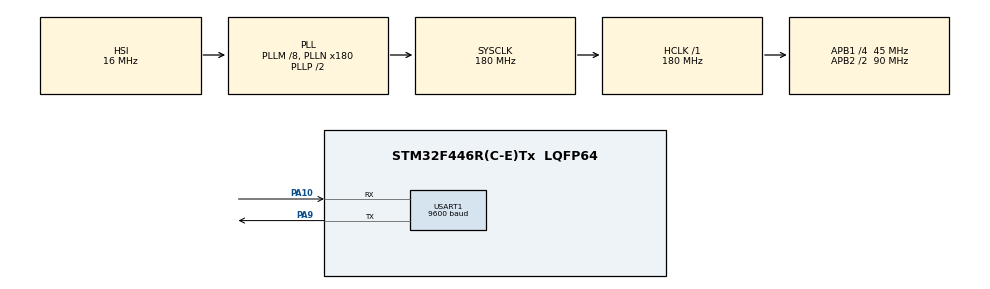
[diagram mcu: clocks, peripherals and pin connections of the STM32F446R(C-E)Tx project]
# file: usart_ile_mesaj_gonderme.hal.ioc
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Dma.Request0=USART1_TX
Dma.USART1_TX.0.Direction=DMA_MEMORY_TO_PERIPH
Dma.USART1_TX.0.FIFOMode=DMA_FIFOMODE_DISABLE
Dma.USART1_TX.0.Instance=DMA2_Stream7
Dma.USART1_TX.0.MemDataAlignment=DMA_MDATAALIGN_BYTE
Dma.USART1_TX.0.MemInc=DMA_MINC_ENABLE
Dma.USART1_TX.0.Mode=DMA_CIRCULAR
Dma.USART1_TX.0.PeriphDataAlignment=DMA_PDATAALIGN_BYTE
Dma.USART1_TX.0.PeriphInc=DMA_PINC_DISABLE
Dma.USART1_TX.0.Priority=DMA_PRIORITY_LOW
Mcu.Family=STM32F4
Mcu.Name=STM32F446R(C-E)Tx
Mcu.Package=LQFP64
NVIC.DMA2_Stream7_IRQn=true\:0\:0\:false\:false\:true\:false\:true\:true
NVIC.PriorityGroup=NVIC_PRIORITYGROUP_4
NVIC.USART1_IRQn=true\:0\:0\:false\:false\:true\:true\:true\:true
PA10.Mode=Asynchronous
PA10.Signal=USART1_RX
PA13.Mode=Serial_Wire
PA13.Signal=SYS_JTMS-SWDIO
PA14.Mode=Serial_Wire
PA14.Signal=SYS_JTCK-SWCLK
PA9.Mode=Asynchronous
PA9.Signal=USART1_TX
ProjectManager.HeapSize=0x200
ProjectManager.StackSize=0x400
ProjectManager.TargetToolchain=STM32CubeIDE
RCC.AHBFreq_Value=180000000
RCC.APB1CLKDivider=RCC_HCLK_DIV4
RCC.APB1Freq_Value=45000000
RCC.APB1TimFreq_Value=90000000
RCC.APB2CLKDivider=RCC_HCLK_DIV2
RCC.APB2Freq_Value=90000000
RCC.APB2TimFreq_Value=180000000
RCC.CortexFreq_Value=180000000
RCC.HCLKFreq_Value=180000000
RCC.PLLM=8
RCC.PLLN=180
RCC.SYSCLKFreq_VALUE=180000000
RCC.SYSCLKSource=RCC_SYSCLKSOURCE_PLLCLK
RCC.USBFreq_Value=180000000
RCC.VCOOutputFreq_Value=360000000
USART1.BaudRate=9600
USART1.VirtualMode=VM_ASYNC
board=custom

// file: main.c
/* USER CODE BEGIN Header */
/**
  ******************************************************************************
  * @file           : main.c
  * @brief          : Main program body
  ******************************************************************************
  * @attention
  *
  * Copyright (c) 2023 STMicroelectronics.
  * All rights reserved.
  *
  * This software is licensed under terms that can be found in the LICENSE file
  * in the root directory of this software component.
  * If no LICENSE file comes with this software, it is provided AS-IS.
  *
  ******************************************************************************
  */
/* USER CODE END Header */
#include "main.h"

/* USER CODE BEGIN Includes */
#include "stdio.h"
#include "string.h"
/* USER CODE END Includes */

UART_HandleTypeDef huart1;
DMA_HandleTypeDef hdma_usart1_tx;

/* USER CODE BEGIN PV */
char tx_buff[50];
uint8_t vize=65,final=87;
float ortalama;

int time1, time;
/* USER CODE END PV */

void SystemClock_Config(void);
static void MX_GPIO_Init(void);
static void MX_DMA_Init(void);
static void MX_USART1_UART_Init(void);

/* USER CODE BEGIN 0 */
void HAL_UART_TxCpltCallback(UART_HandleTypeDef *huart)
{
	//HAL_UART_Transmit_IT(&huart1, tx_buff, strlen(tx_buff));
}

/*
int _write(int file, char *ptr, int len)
{
	HAL_UART_Transmit(&huart1, (uint8_t *)ptr, len, HAL_MAX_DELAY);
	return len;
}
*/
/* USER CODE END 0 */

int main(void)
{

  /* MCU Configuration--------------------------------------------------------*/

  /* Reset of all peripherals, Initializes the Flash interface and the Systick. */
  HAL_Init();

  /* Configure the system clock */
  SystemClock_Config();

  /* Initialize all configured peripherals */
  MX_GPIO_Init();
  MX_DMA_Init();
  MX_USART1_UART_Init();
  /* USER CODE BEGIN 2 */
  ortalama=(vize * 0.4) + (final * 0.6);
  sprintf(tx_buff,"Vize:%d, Final:%d, Ortalama:%.2f\r\n",vize,final,ortalama);

  //HAL_UART_Transmit_IT(&huart1, tx_buff, strlen(tx_buff));

  HAL_UART_Transmit_DMA(&huart1, tx_buff, strlen(tx_buff));
  /* USER CODE END 2 */

  /* Infinite loop */
  while (1)
  {

    /* USER CODE BEGIN 3 */
	  //HAL_UART_Transmit (&huart1, tx_buff, strlen(tx_buff), 100);
	  //printf("Vize: %d, Final:%d, Ortalama:%.2f\r\n",vize,final,ortalama);
	  //HAL_Delay(500);

	  //HAL_UART_Transmit_IT(&huart1, tx_buff, strlen(tx_buff));

	  //HAL_UART_Transmit_DMA(&huart1, tx_buff, strlen(tx_buff));

	  //HAL_Delay(500);
  }
  /* USER CODE END 3 */
}

void SystemClock_Config(void)
{
  RCC_OscInitTypeDef RCC_OscInitStruct = {0};
  RCC_ClkInitTypeDef RCC_ClkInitStruct = {0};

  /** Configure the main internal regulator output voltage
  */
  __HAL_RCC_PWR_CLK_ENABLE();
  __HAL_PWR_VOLTAGESCALING_CONFIG(PWR_REGULATOR_VOLTAGE_SCALE1);

  /** Initializes the RCC Oscillators according to the specified parameters
  * in the RCC_OscInitTypeDef structure.
  */
  RCC_OscInitStruct.OscillatorType = RCC_OSCILLATORTYPE_HSI;
  RCC_OscInitStruct.HSIState = RCC_HSI_ON;
  RCC_OscInitStruct.HSICalibrationValue = RCC_HSICALIBRATION_DEFAULT;
  RCC_OscInitStruct.PLL.PLLState = RCC_PLL_ON;
  RCC_OscInitStruct.PLL.PLLSource = RCC_PLLSOURCE_HSI;
  RCC_OscInitStruct.PLL.PLLM = 8;
  RCC_OscInitStruct.PLL.PLLN = 180;
  RCC_OscInitStruct.PLL.PLLP = RCC_PLLP_DIV2;
  RCC_OscInitStruct.PLL.PLLQ = 2;
  RCC_OscInitStruct.PLL.PLLR = 2;
  if (HAL_RCC_OscConfig(&RCC_OscInitStruct) != HAL_OK)
  {
    Error_Handler();
  }

  /** Activate the Over-Drive mode
  */
  if (HAL_PWREx_EnableOverDrive() != HAL_OK)
  {
    Error_Handler();
  }

  /** Initializes the CPU, AHB and APB buses clocks
  */
  RCC_ClkInitStruct.ClockType = RCC_CLOCKTYPE_HCLK|RCC_CLOCKTYPE_SYSCLK
                              |RCC_CLOCKTYPE_PCLK1|RCC_CLOCKTYPE_PCLK2;
  RCC_ClkInitStruct.SYSCLKSource = RCC_SYSCLKSOURCE_PLLCLK;
  RCC_ClkInitStruct.AHBCLKDivider = RCC_SYSCLK_DIV1;
  RCC_ClkInitStruct.APB1CLKDivider = RCC_HCLK_DIV4;
  RCC_ClkInitStruct.APB2CLKDivider = RCC_HCLK_DIV2;

  if (HAL_RCC_ClockConfig(&RCC_ClkInitStruct, FLASH_LATENCY_5) != HAL_OK)
  {
    Error_Handler();
  }
}

static void MX_USART1_UART_Init(void)
{

  huart1.Instance = USART1;
  huart1.Init.BaudRate = 9600;
  huart1.Init.WordLength = UART_WORDLENGTH_8B;
  huart1.Init.StopBits = UART_STOPBITS_1;
  huart1.Init.Parity = UART_PARITY_NONE;
  huart1.Init.Mode = UART_MODE_TX_RX;
  huart1.Init.HwFlowCtl = UART_HWCONTROL_NONE;
  huart1.Init.OverSampling = UART_OVERSAMPLING_16;
  if (HAL_UART_Init(&huart1) != HAL_OK)
  {
    Error_Handler();
  }

}

static void MX_DMA_Init(void)
{

  /* DMA controller clock enable */
  __HAL_RCC_DMA2_CLK_ENABLE();

  /* DMA interrupt init */
  /* DMA2_Stream7_IRQn interrupt configuration */
  HAL_NVIC_SetPriority(DMA2_Stream7_IRQn, 0, 0);
  HAL_NVIC_EnableIRQ(DMA2_Stream7_IRQn);

}

static void MX_GPIO_Init(void)
{

  /* GPIO Ports Clock Enable */
  __HAL_RCC_GPIOA_CLK_ENABLE();

}

void Error_Handler(void)
{
  __disable_irq();
  while (1)
  {
  }
}
